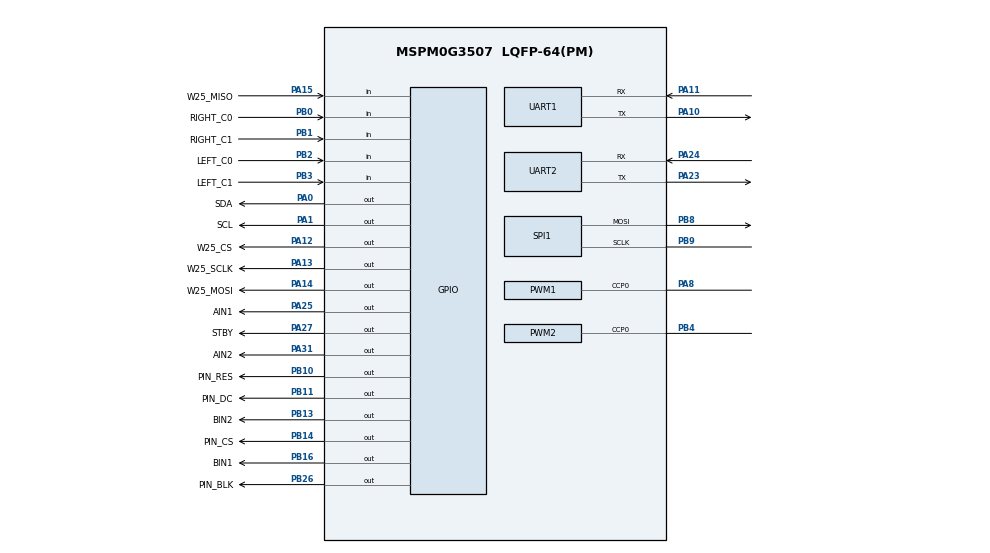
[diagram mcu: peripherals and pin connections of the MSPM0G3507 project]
//@cliArgs --device "MSPM0G350X" --package "LQFP-64(PM)" --part "Default"
//@v2CliArgs --device "MSPM0G3507" --package "LQFP-64(PM)"
// @cliArgs --board /ti/boards/LP_MSPM0G3507 --rtos nortos

/**
 * Import the modules used in this configuration.
 */
const GPIO   = scripting.addModule("/ti/driverlib/GPIO", {}, false);
const GPIO1  = GPIO.addInstance();
const GPIO2  = GPIO.addInstance();
const GPIO3  = GPIO.addInstance();
const GPIO4  = GPIO.addInstance();
const GPIO5  = GPIO.addInstance();
const GPIO6  = GPIO.addInstance();
const GPIO7  = GPIO.addInstance();
const GPIO8  = GPIO.addInstance();
const PWM    = scripting.addModule("/ti/driverlib/PWM", {}, false);
const PWM1   = PWM.addInstance();
const PWM2   = PWM.addInstance();
const SPI    = scripting.addModule("/ti/driverlib/SPI", {}, false);
const SPI1   = SPI.addInstance();
const SYSCTL = scripting.addModule("/ti/driverlib/SYSCTL");
const UART   = scripting.addModule("/ti/driverlib/UART", {}, false);
const UART1  = UART.addInstance();
const UART2  = UART.addInstance();

/**
 * Write custom configuration values to the imported modules.
 */
GPIO1.$name                        = "GPIO_MOTOR_A";
GPIO1.port                         = "PORTA";
GPIO1.associatedPins.create(3);
GPIO1.associatedPins[0].$name      = "AIN1";
GPIO1.associatedPins[0].pin.$assign = "PA25";
GPIO1.associatedPins[1].$name      = "AIN2";
GPIO1.associatedPins[1].pin.$assign = "PA31";
GPIO1.associatedPins[2].$name      = "STBY";
GPIO1.associatedPins[2].pin.$assign = "PA27";

GPIO2.$name                        = "GPIO_MOTOR_B";
GPIO2.port                         = "PORTB";
GPIO2.associatedPins.create(2);
GPIO2.associatedPins[0].$name      = "BIN1";
GPIO2.associatedPins[0].pin.$assign = "PB16";
GPIO2.associatedPins[1].$name      = "BIN2";
GPIO2.associatedPins[1].pin.$assign = "PB13";

GPIO3.$name                         = "GPIO_STATUS_LED";
GPIO3.port                          = "PORTB";
GPIO3.associatedPins.create(1);
GPIO3.associatedPins[0].$name       = "PB22_LED";
GPIO3.associatedPins[0].assignedPin = "22";

GPIO4.$name                         = "GPIO_ENCODER_LEFT";
GPIO4.port                          = "PORTB";
GPIO4.associatedPins.create(2);
GPIO4.associatedPins[0].$name       = "LEFT_C0";
GPIO4.associatedPins[0].pin.$assign = "PB2";
GPIO4.associatedPins[0].direction   = "INPUT";
GPIO4.associatedPins[0].internalResistor = "PULL_UP";
GPIO4.associatedPins[0].interruptEn = true;
GPIO4.associatedPins[0].interruptPriority = "0";
GPIO4.associatedPins[0].polarity = "RISE";
GPIO4.associatedPins[1].$name       = "LEFT_C1";
GPIO4.associatedPins[1].pin.$assign = "PB3";
GPIO4.associatedPins[1].direction   = "INPUT";
GPIO4.associatedPins[1].internalResistor = "PULL_UP";
GPIO4.associatedPins[1].interruptEn = true;
GPIO4.associatedPins[1].interruptPriority = "0";
GPIO4.associatedPins[1].polarity = "RISE";

GPIO5.$name                         = "GPIO_ENCODER_RIGHT";
GPIO5.port                          = "PORTB";
GPIO5.associatedPins.create(2);
GPIO5.associatedPins[0].$name       = "RIGHT_C0";
GPIO5.associatedPins[0].pin.$assign = "PB0";
GPIO5.associatedPins[0].direction   = "INPUT";
GPIO5.associatedPins[0].internalResistor = "PULL_UP";
GPIO5.associatedPins[0].interruptEn = true;
GPIO5.associatedPins[0].interruptPriority = "0";
GPIO5.associatedPins[0].polarity = "RISE";
GPIO5.associatedPins[1].$name       = "RIGHT_C1";
GPIO5.associatedPins[1].pin.$assign = "PB1";
GPIO5.associatedPins[1].direction   = "INPUT";
GPIO5.associatedPins[1].internalResistor = "PULL_UP";
GPIO5.associatedPins[1].interruptEn = true;
GPIO5.associatedPins[1].interruptPriority = "0";
GPIO5.associatedPins[1].polarity = "RISE";

GPIO6.$name                          = "GPIO_MPU6050_I2C";
GPIO6.port                           = "PORTA";
GPIO6.associatedPins.create(2);
GPIO6.associatedPins[0].$name        = "SCL";
GPIO6.associatedPins[0].pin.$assign  = "PA1";
GPIO6.associatedPins[0].initialValue = "SET";
GPIO6.associatedPins[0].ioStructure  = "OD";
GPIO6.associatedPins[0].internalResistor = "PULL_UP";
GPIO6.associatedPins[1].$name        = "SDA";
GPIO6.associatedPins[1].pin.$assign  = "PA0";
GPIO6.associatedPins[1].initialValue = "SET";
GPIO6.associatedPins[1].ioStructure  = "OD";
GPIO6.associatedPins[1].internalResistor = "PULL_UP";

PWM1.$name                      = "PWM_LEFT";
PWM1.clockPrescale              = 1;
PWM1.timerCount                 = 1600;
PWM1.ccIndex                    = [0];
PWM1.peripheral.$assign         = "TIMA0";
PWM1.peripheral.ccp0Pin.$assign = "PA8";
PWM1.PWM_CHANNEL_0.$name        = "PWMA";
PWM1.PWM_CHANNEL_0.dutyCycle    = 60;

PWM2.$name                      = "PWM_RIGHT";
PWM2.clockPrescale              = 1;
PWM2.timerCount                 = 1600;
PWM2.ccIndex                    = [0];
PWM2.peripheral.$assign         = "TIMA1";
PWM2.peripheral.ccp0Pin.$assign = "PB4";
PWM2.PWM_CHANNEL_0.$name        = "PWMB";
PWM2.PWM_CHANNEL_0.dutyCycle    = 60;

UART1.$name                    = "UART_DEBUG";
UART1.targetBaudRate           = 115200;
UART1.enableFIFO               = true;
UART1.rxFifoThreshold          = "DL_UART_RX_FIFO_LEVEL_ONE_ENTRY";
UART1.txFifoThreshold          = "DL_UART_TX_FIFO_LEVEL_1_2_EMPTY";
UART1.peripheral.$assign       = "UART0";
UART1.peripheral.rxPin.$assign = "PA11";
UART1.peripheral.txPin.$assign = "PA10";

UART2.$name                    = "UART_OPENMV";
UART2.targetBaudRate           = 115200;
UART2.enableFIFO               = true;
UART2.rxFifoThreshold          = "DL_UART_RX_FIFO_LEVEL_ONE_ENTRY";
UART2.txFifoThreshold          = "DL_UART_TX_FIFO_LEVEL_1_2_EMPTY";
UART2.peripheral.$assign       = "UART2";
UART2.peripheral.rxPin.$assign = "PA24";
UART2.peripheral.txPin.$assign = "PA23";

GPIO7.$name                          = "GPIO_LCD";
GPIO7.port                           = "PORTB";
GPIO7.associatedPins.create(4);
GPIO7.associatedPins[0].$name        = "PIN_RES";
GPIO7.associatedPins[0].pin.$assign  = "PB10";
GPIO7.associatedPins[1].$name        = "PIN_DC";
GPIO7.associatedPins[1].pin.$assign  = "PB11";
GPIO7.associatedPins[2].$name        = "PIN_CS";
GPIO7.associatedPins[2].initialValue = "SET";
GPIO7.associatedPins[2].pin.$assign  = "PB14";
GPIO7.associatedPins[3].$name        = "PIN_BLK";
GPIO7.associatedPins[3].pin.$assign  = "PB26";

GPIO8.$name                          = "GPIO_W25Q64";
GPIO8.port                           = "PORTA";
GPIO8.associatedPins.create(4);
GPIO8.associatedPins[0].$name        = "W25_CS";
GPIO8.associatedPins[0].pin.$assign  = "PA12";
GPIO8.associatedPins[0].initialValue = "SET";
GPIO8.associatedPins[1].$name        = "W25_SCLK";
GPIO8.associatedPins[1].pin.$assign  = "PA13";
GPIO8.associatedPins[2].$name        = "W25_MOSI";
GPIO8.associatedPins[2].pin.$assign  = "PA14";
GPIO8.associatedPins[3].$name        = "W25_MISO";
GPIO8.associatedPins[3].pin.$assign  = "PA15";
GPIO8.associatedPins[3].direction    = "INPUT";
GPIO8.associatedPins[3].internalResistor = "PULL_UP";

SPI1.$name                              = "SPI_LCD";
SPI1.frameFormat                        = "MOTO3";
SPI1.direction                          = "PICO";
SPI1.targetBitRate                      = 16000000;
SPI1.sclkPinConfig.direction            = scripting.forceWrite("OUTPUT");
SPI1.sclkPinConfig.onlyInternalResistor = scripting.forceWrite(false);
SPI1.sclkPinConfig.passedPeripheralType = scripting.forceWrite("Digital");
SPI1.sclkPinConfig.$name                = "ti_driverlib_gpio_LCD_SCLK";
SPI1.mosiPinConfig.direction            = scripting.forceWrite("OUTPUT");
SPI1.mosiPinConfig.hideOutputInversion  = scripting.forceWrite(false);
SPI1.mosiPinConfig.onlyInternalResistor = scripting.forceWrite(false);
SPI1.mosiPinConfig.passedPeripheralType = scripting.forceWrite("Digital");
SPI1.mosiPinConfig.$name                = "ti_driverlib_gpio_LCD_MOSI";
SPI1.peripheral.sclkPin.$assign         = "PB9";
SPI1.peripheral.mosiPin.$assign         = "PB8";

const Board = scripting.addModule("/ti/driverlib/Board", {}, false);

SYSCTL.forceDefaultClkConfig = true;
SYSCTL.clockTreeEn  = true;
